# SKEAZN642 register map
Vendor: Freescale Semiconductor, Inc.; File version: 1.6
SKEAZN642 Freescale Microcontroller
CPU: CM0PLUS r0p0, little endian, no MPU, no FPU, 0x2 interrupt priority bits, 0x0 interrupts
Registers are 32-bit, read-write, reset 0x0 unless marked. A register's access mark holds for its fields unless they carry their own. Offsets are from the block's base; lines under a group give offsets from that group; [hi:lo] are bit positions; {n}, {i} and the like mark numbered series; 'fields as' and 'values as' point back to an identical list; <NAME> marks a mode.

## Memory map
0x00000400 FTMRH_FlashConfig size 0x10 — Flash configuration field
0x40020000 FTMRH size 0xD — Flash Memory
0x40031000 IRQ size 0x1 — Interrupt
0x40032000 CRC size 0xC — Cyclic Redundancy Check
0x40037000 PIT size 0x120 — Periodic Interrupt Timer
0x40038000 FTM0 size 0x1C — FlexTimer Module
0x40039000 FTM1 size 0x1C — FlexTimer Module
0x4003A000 FTM2 size 0x9C — FlexTimer Module
0x4003B000 ADC size 0x1C — Analog-to-digital converter
0x4003D000 RTC size 0xC — Real-time counter
0x40048000 SIM size 0x1C — System Integration Module
0x40049000 PORT size 0x10 — Port control and interrupts
0x40052000 WDOG size 0x8 — Watchdog timer
0x40064000 ICS size 0x5 — Clock management
0x40065000 OSC size 0x1 — Oscillator
0x40066000 I2C0 size 0xC — Inter-Integrated Circuit
0x4006A000 UART0 size 0x8 — Universal Asynchronous Receiver/Transmitter (UART)
0x4006B000 UART1 size 0x8 — Universal Asynchronous Receiver/Transmitter (UART)
0x4006C000 UART2 size 0x8 — Universal Asynchronous Receiver/Transmitter (UART)
0x40073000 ACMP0 size 0x4 — Analog comparator
0x40074000 ACMP1 size 0x4 — Analog comparator
0x40076000 SPI0 size 0x8 — Serial Peripheral Interface
0x40077000 SPI1 size 0x8 — Serial Peripheral Interface
0x40079000 KBI0 size 0x3 — Keyboard interrupts
0x4007A000 KBI1 size 0x3 — Keyboard interrupts
0x4007D000 PMC size 0x2 — Power management
0x400FF000 GPIOA size 0x1C — General Purpose Input/Output
0x400FF040 GPIOB size 0x1C — General Purpose Input/Output
0xE000E000 SystemControl blocks up to offset 0xD34 — System Control Registers
0xE000E010 SysTick size 0x10 — System timer
0xE000E100 NVIC size 0x320 — Nested Vectored Interrupt Controller
0xF0002000 ROM size 0x1000 — System ROM
0xF0003000 MCM blocks up to offset 0x10 — Core Platform Miscellaneous Control Module
0xF8000000 FGPIOA size 0x1C — General Purpose Input/Output
0xF8000040 FGPIOB size 0x1C — General Purpose Input/Output

## Interrupts
5 FTMRH
6 LVD_LVW (PMC)
7 IRQ
8 I2C0
10 SPI0
11 SPI1
12 UART0
13 UART1
14 UART2
15 ADC0 (ADC)
16 ACMP0
17 FTM0
18 FTM1
19 FTM2
20 RTC
21 ACMP1
22 PIT_CH0 (PIT)
23 PIT_CH1 (PIT)
24 KBI0
25 KBI1
27 ICS
28 WDOG_EWM (WDOG)

## FTMRH_FlashConfig — Flash configuration field
Base 0x00000400; register names take the prefix NV_
{0x0+i} BACKKEY{i} 8-bit ro reset 0xFF (i=0..7) — Backdoor Comparison Key {i}
  [7:0] KEY — Backdoor Comparison Key.
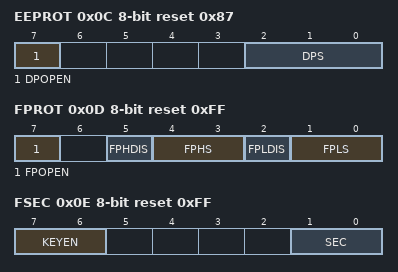
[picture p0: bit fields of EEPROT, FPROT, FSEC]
0x0C EEPROT 8-bit ro reset 0x87 — Non-volatile E-Flash Protection Register
  [7] DPOPEN
    0=Enables EEPROM memory protection; 1=Disables EEPROM memory protection
  [2:0] DPS
    0=Flash address range: 0x00_0000 - 0x00_001F; protected size: 32 bytes; 1=Flash address range: 0x00_0000 - 0x00_003F; protected size: 64 bytes; 2=Flash address range: 0x00_0000 - 0x00_005F; protected size: 96 bytes; 3=Flash address range: 0x00_0000 - 0x00_007F; protected size: 128 bytes; 4=Flash address range: 0x00_0000 - 0x00_009F; protected size: 160 bytes; 5=Flash address range: 0x00_0000 - 0x00_00BF; protected size: 192 bytes; 6=Flash address range: 0x00_0000 - 0x00_00DF; protected size: 224 bytes; 7=Flash address range: 0x00_0000 - 0x00_00FF; protected size: 256 bytes
0x0D FPROT 8-bit ro reset 0xFF — Non-volatile P-Flash Protection Register
  [7] FPOPEN
    0=FPHDIS and FPLDIS bits define unprotected address ranges as specified by the corresponding FPHS and FPLS bits FPROT1.1; 1=FPHDIS and FPLDIS bits enable protection for the address range specified by the corresponding FPHS and FPLS bits
  [5] FPHDIS
    0=Protection/Unprotection enabled; 1=Protection/Unprotection disabled
  [4:3] FPHS
    0=Address range: 0x00_7C00-0x00_7FFF; protected size: 1 KB; 1=Address range: 0x00_7800-0x00_7FFF; protected size: 2 KB; 2=Address range: 0x00_7000-0x00_7FFF; protected size: 4 KB; 3=Address range: 0x00_6000-0x00_7FFF; protected size: 8 KB
  [2] FPLDIS
    values as FPHDIS
  [1:0] FPLS
    0=Address range: 0x00_0000-0x00_07FF; protected size: 2 KB; 1=Address range: 0x00_0000-0x00_0FFF; protected size: 4 KB; 2=Address range: 0x00_0000-0x00_1FFF; protected size: 8 KB; 3=Address range: 0x00_0000-0x00_3FFF; protected size: 16 KB
0x0E FSEC 8-bit ro reset 0xFF — Non-volatile Flash Security Register
  [7:6] KEYEN — Backdoor Key Security Enable
    2=Backdoor key access enabled; 3=Backdoor key access disabled
  [1:0] SEC — Flash Security
    2=MCU security status is unsecure; 3=MCU security status is secure
0x0F FOPT 8-bit ro reset 0xFF — Non-volatile Flash Option Register
